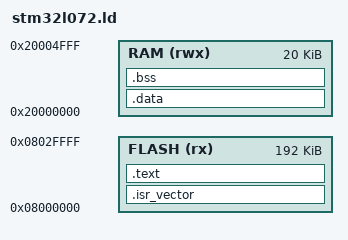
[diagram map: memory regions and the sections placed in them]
/* Linker script for STM32L072CZT6 (Nucleo-L073RZ)
   - 192KB flash at 0x08000000
   - 20KB SRAM at 0x20000000 */

MEMORY {
    FLASH (rx)  : ORIGIN = 0x08000000, LENGTH = 192K
    RAM   (rwx) : ORIGIN = 0x20000000, LENGTH = 20K
}

ENTRY(resetHandler)

_stack_top = ORIGIN(RAM) + LENGTH(RAM);

SECTIONS {
    .isr_vector : {
        KEEP(*(.isr_vector))
        . = ALIGN(4);
    } > FLASH

    .text : {
        *(.text)
        *(.text.*)
        *(.rodata)
        *(.rodata.*)
        . = ALIGN(4);
        _etext = .;
    } > FLASH

    _sidata = LOADADDR(.data);

    .data : AT(_etext) {
        . = ALIGN(4);
        _sdata = .;
        *(.data)
        *(.data.*)
        . = ALIGN(4);
        _edata = .;
    } > RAM

    .bss (NOLOAD) : {
        . = ALIGN(4);
        _sbss = .;
        *(.bss)
        *(.bss.*)
        *(COMMON)
        . = ALIGN(4);
        _ebss = .;
    } > RAM

    /DISCARD/ : {
        *(.ARM.exidx*)
        *(.ARM.extab*)
        *(.ARM.attributes*)
        *(.comment)
    }
}
